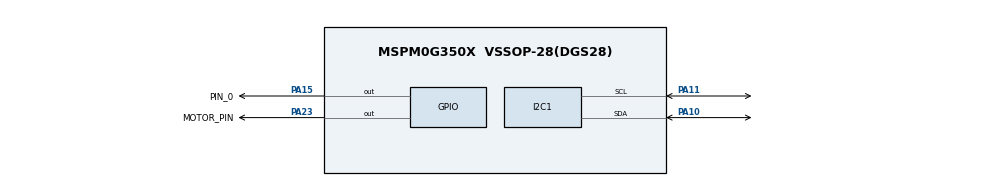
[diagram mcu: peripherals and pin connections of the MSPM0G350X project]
/**
 * @cliArgs --device "MSPM0G350X" --part "Default" --package "VSSOP-28(DGS28)" --product "mspm0_sdk@2.03.00.08"
 * @versions {"tool":"1.21.0+3721"}
 */

/**
 * Import the modules used in this configuration.
 */
const GPIO  = scripting.addModule("/ti/driverlib/GPIO", {}, false);
const GPIO1 = GPIO.addInstance();
const GPIO2 = GPIO.addInstance();
const I2C   = scripting.addModule("/ti/driverlib/I2C", {}, false);
const I2C1  = I2C.addInstance();

/**
 * Write custom configuration values to the imported modules.
 */
GPIO1.$name                         = "MOTOR";
GPIO1.port                          = "PORTA";
GPIO1.associatedPins[0].$name       = "MOTOR_PIN";
GPIO1.associatedPins[0].assignedPin = "23";
GPIO1.associatedPins[0].pin.$assign = "PA23";

const Board = scripting.addModule("/ti/driverlib/Board", {}, false);

GPIO2.$name                         = "BUZZER_IO";
GPIO2.port                          = "PORTA";
GPIO2.associatedPins[0].$name       = "PIN_0";
GPIO2.associatedPins[0].assignedPin = "15";
GPIO2.associatedPins[0].pin.$assign = "PA15";

I2C1.$name                             = "I2C0";
I2C1.peripheral.$assign                = "I2C0";
I2C1.peripheral.sdaPin.$assign         = "PA10";
I2C1.peripheral.sclPin.$assign         = "PA11";
I2C1.sdaPinConfig.$name                = "ti_driverlib_gpio_GPIOPinGeneric0";
I2C1.sdaPinConfig.hideOutputInversion  = scripting.forceWrite(false);
I2C1.sdaPinConfig.onlyInternalResistor = scripting.forceWrite(false);
I2C1.sdaPinConfig.passedPeripheralType = scripting.forceWrite("Digital");
I2C1.sclPinConfig.$name                = "ti_driverlib_gpio_GPIOPinGeneric1";
I2C1.sclPinConfig.hideOutputInversion  = scripting.forceWrite(false);
I2C1.sclPinConfig.onlyInternalResistor = scripting.forceWrite(false);
I2C1.sclPinConfig.passedPeripheralType = scripting.forceWrite("Digital");

const SYSCTL = scripting.addModule("/ti/driverlib/SYSCTL", {}, false);

const ProjectConfig              = scripting.addModule("/ti/project_config/ProjectConfig", {}, false);
ProjectConfig.migrationCondition = true;

/**
 * Pinmux solution for unlocked pins/peripherals. This ensures that minor changes to the automatic solver in a future
 * version of the tool will not impact the pinmux you originally saw.  These lines can be completely deleted in order to
 * re-solve from scratch.
 */
Board.peripheral.$suggestSolution          = "DEBUGSS";
Board.peripheral.swclkPin.$suggestSolution = "PA20";
Board.peripheral.swdioPin.$suggestSolution = "PA19";
SYSCTL.peripheral.$suggestSolution         = "SYSCTL";
